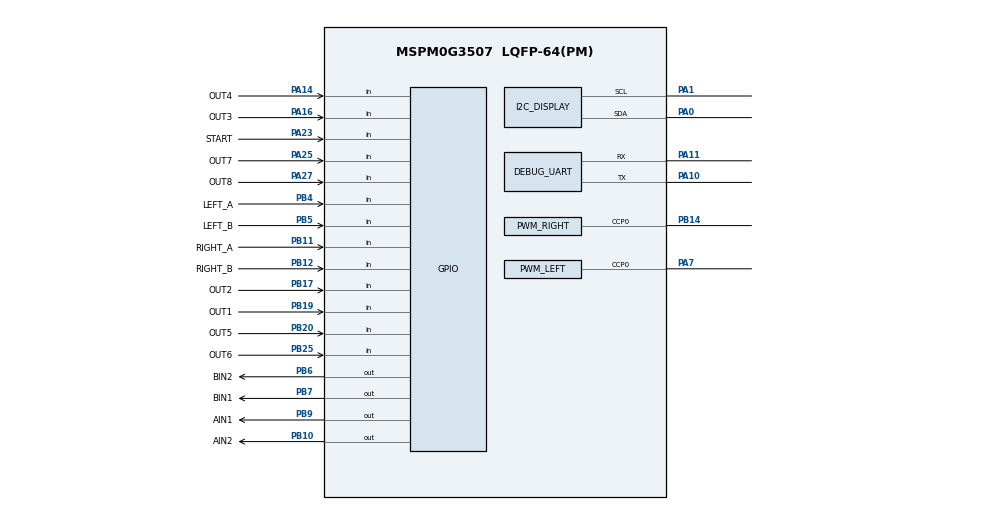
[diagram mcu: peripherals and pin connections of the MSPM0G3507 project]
/**
 * @cliArgs --device "MSPM0G350X" --part "Default" --package "LQFP-64(PM)" --product "mspm0_sdk@2.10.00.04"
 * @v2CliArgs --device "MSPM0G3507" --package "LQFP-64(PM)" --product "mspm0_sdk@2.10.00.04"
 * @versions {"tool":"1.27.1+4634"}
 */

const GPIO   = scripting.addModule("/ti/driverlib/GPIO", {}, false);
const MOTOR_DIR = GPIO.addInstance();
const ENCODER   = GPIO.addInstance();
const LINE      = GPIO.addInstance();
const USER_KEY  = GPIO.addInstance();
const I2C    = scripting.addModule("/ti/driverlib/I2C", {}, false);
const I2C_DISPLAY = I2C.addInstance();
const PWM    = scripting.addModule("/ti/driverlib/PWM", {}, false);
const PWM_RIGHT = PWM.addInstance();
const PWM_LEFT  = PWM.addInstance();
const SYSCTL = scripting.addModule("/ti/driverlib/SYSCTL");
const TIMER  = scripting.addModule("/ti/driverlib/TIMER", {}, false);
const CONTROL_TIMER = TIMER.addInstance();
const UART   = scripting.addModule("/ti/driverlib/UART", {}, false);
const DEBUG_UART = UART.addInstance();
const Board = scripting.addModule("/ti/driverlib/Board", {}, false);

const gate7 = system.clockTree["MFCLKGATE"];
gate7.enable = true;

MOTOR_DIR.$name = "MOTOR_DIR";
MOTOR_DIR.associatedPins.create(4);
MOTOR_DIR.associatedPins[0].$name = "AIN1";
MOTOR_DIR.associatedPins[0].pin.$assign = "PB9";
MOTOR_DIR.associatedPins[1].$name = "AIN2";
MOTOR_DIR.associatedPins[1].pin.$assign = "PB10";
MOTOR_DIR.associatedPins[2].$name = "BIN1";
MOTOR_DIR.associatedPins[2].pin.$assign = "PB7";
MOTOR_DIR.associatedPins[3].$name = "BIN2";
MOTOR_DIR.associatedPins[3].pin.$assign = "PB6";

ENCODER.$name = "ENCODER";
ENCODER.associatedPins.create(4);
ENCODER.associatedPins[0].$name = "RIGHT_A";
ENCODER.associatedPins[0].direction = "INPUT";
ENCODER.associatedPins[0].internalResistor = "PULL_UP";
ENCODER.associatedPins[0].interruptEn = true;
ENCODER.associatedPins[0].polarity = "RISE_FALL";
ENCODER.associatedPins[0].pin.$assign = "PB11";
ENCODER.associatedPins[1].$name = "RIGHT_B";
ENCODER.associatedPins[1].direction = "INPUT";
ENCODER.associatedPins[1].internalResistor = "PULL_UP";
ENCODER.associatedPins[1].pin.$assign = "PB12";
ENCODER.associatedPins[2].$name = "LEFT_A";
ENCODER.associatedPins[2].direction = "INPUT";
ENCODER.associatedPins[2].internalResistor = "PULL_UP";
ENCODER.associatedPins[2].interruptEn = true;
ENCODER.associatedPins[2].polarity = "RISE_FALL";
ENCODER.associatedPins[2].pin.$assign = "PB4";
ENCODER.associatedPins[3].$name = "LEFT_B";
ENCODER.associatedPins[3].direction = "INPUT";
ENCODER.associatedPins[3].internalResistor = "PULL_UP";
ENCODER.associatedPins[3].pin.$assign = "PB5";

LINE.$name = "LINE";
LINE.associatedPins.create(8);
LINE.associatedPins[0].$name = "OUT1";
LINE.associatedPins[0].direction = "INPUT";
LINE.associatedPins[0].internalResistor = "PULL_UP";
LINE.associatedPins[0].pin.$assign = "PB19";
LINE.associatedPins[1].$name = "OUT2";
LINE.associatedPins[1].direction = "INPUT";
LINE.associatedPins[1].internalResistor = "PULL_UP";
LINE.associatedPins[1].pin.$assign = "PB17";
LINE.associatedPins[2].$name = "OUT3";
LINE.associatedPins[2].direction = "INPUT";
LINE.associatedPins[2].internalResistor = "PULL_UP";
LINE.associatedPins[2].pin.$assign = "PA16";
LINE.associatedPins[3].$name = "OUT4";
LINE.associatedPins[3].direction = "INPUT";
LINE.associatedPins[3].internalResistor = "PULL_UP";
LINE.associatedPins[3].pin.$assign = "PA14";
LINE.associatedPins[4].$name = "OUT5";
LINE.associatedPins[4].direction = "INPUT";
LINE.associatedPins[4].internalResistor = "PULL_UP";
LINE.associatedPins[4].pin.$assign = "PB20";
LINE.associatedPins[5].$name = "OUT6";
LINE.associatedPins[5].direction = "INPUT";
LINE.associatedPins[5].internalResistor = "PULL_UP";
LINE.associatedPins[5].pin.$assign = "PB25";
LINE.associatedPins[6].$name = "OUT7";
LINE.associatedPins[6].direction = "INPUT";
LINE.associatedPins[6].internalResistor = "PULL_UP";
LINE.associatedPins[6].pin.$assign = "PA25";
LINE.associatedPins[7].$name = "OUT8";
LINE.associatedPins[7].direction = "INPUT";
LINE.associatedPins[7].internalResistor = "PULL_UP";
LINE.associatedPins[7].pin.$assign = "PA27";

USER_KEY.$name = "USER_KEY";
USER_KEY.associatedPins.create(1);
USER_KEY.associatedPins[0].$name = "START";
USER_KEY.associatedPins[0].direction = "INPUT";
USER_KEY.associatedPins[0].internalResistor = "PULL_UP";
USER_KEY.associatedPins[0].interruptEn = true;
USER_KEY.associatedPins[0].polarity = "FALL";
USER_KEY.associatedPins[0].pin.$assign = "PA23";

I2C_DISPLAY.$name = "I2C_DISPLAY";
I2C_DISPLAY.basicEnableController = true;
I2C_DISPLAY.basicControllerStandardBusSpeed = "Standard";
I2C_DISPLAY.peripheral.$assign = "I2C0";
I2C_DISPLAY.peripheral.sdaPin.$assign = "PA0";
I2C_DISPLAY.peripheral.sclPin.$assign = "PA1";
I2C_DISPLAY.sdaPinConfig.$name = "ti_driverlib_gpio_GPIOPinGeneric0";
I2C_DISPLAY.sclPinConfig.$name = "ti_driverlib_gpio_GPIOPinGeneric1";

PWM_RIGHT.$name = "PWM_RIGHT";
PWM_RIGHT.timerStartTimer = true;
PWM_RIGHT.timerCount = 2000;
PWM_RIGHT.pwmMode = "EDGE_ALIGN_UP";
PWM_RIGHT.ccIndex = [0];
PWM_RIGHT.peripheral.$assign = "TIMA0";
PWM_RIGHT.peripheral.ccp0Pin.$assign = "PB14";
PWM_RIGHT.PWM_CHANNEL_0.$name = "ti_driverlib_pwm_PWMTimerCC0";
PWM_RIGHT.PWM_CHANNEL_0.dutyCycle = 0;

PWM_LEFT.$name = "PWM_LEFT";
PWM_LEFT.timerStartTimer = true;
PWM_LEFT.timerCount = 2000;
PWM_LEFT.pwmMode = "EDGE_ALIGN_UP";
PWM_LEFT.ccIndex = [0];
PWM_LEFT.peripheral.$assign = "TIMG8";
PWM_LEFT.peripheral.ccp0Pin.$assign = "PA7";
PWM_LEFT.PWM_CHANNEL_0.$name = "ti_driverlib_pwm_PWMTimerCC1";
PWM_LEFT.PWM_CHANNEL_0.dutyCycle = 0;

CONTROL_TIMER.$name = "CONTROL_TIMER";
CONTROL_TIMER.timerMode = "PERIODIC_UP";
CONTROL_TIMER.timerPeriod = "1ms";
CONTROL_TIMER.interrupts = ["LOAD"];
CONTROL_TIMER.timerStartTimer = true;
CONTROL_TIMER.peripheral.$assign = "TIMA1";

DEBUG_UART.$name = "DEBUG_UART";
DEBUG_UART.uartClkSrc = "MFCLK";
DEBUG_UART.targetBaudRate = 115200;
DEBUG_UART.peripheral.$assign = "UART0";
DEBUG_UART.peripheral.rxPin.$assign = "PA11";
DEBUG_UART.peripheral.txPin.$assign = "PA10";
DEBUG_UART.txPinConfig.$name = "ti_driverlib_gpio_GPIOPinGeneric20";
DEBUG_UART.rxPinConfig.$name = "ti_driverlib_gpio_GPIOPinGeneric21";

SYSCTL.forceDefaultClkConfig = true;
SYSCTL.clockTreeEn = true;

Board.peripheral.$suggestSolution = "DEBUGSS";
Board.peripheral.swclkPin.$suggestSolution = "PA20";
Board.peripheral.swdioPin.$suggestSolution = "PA19";
